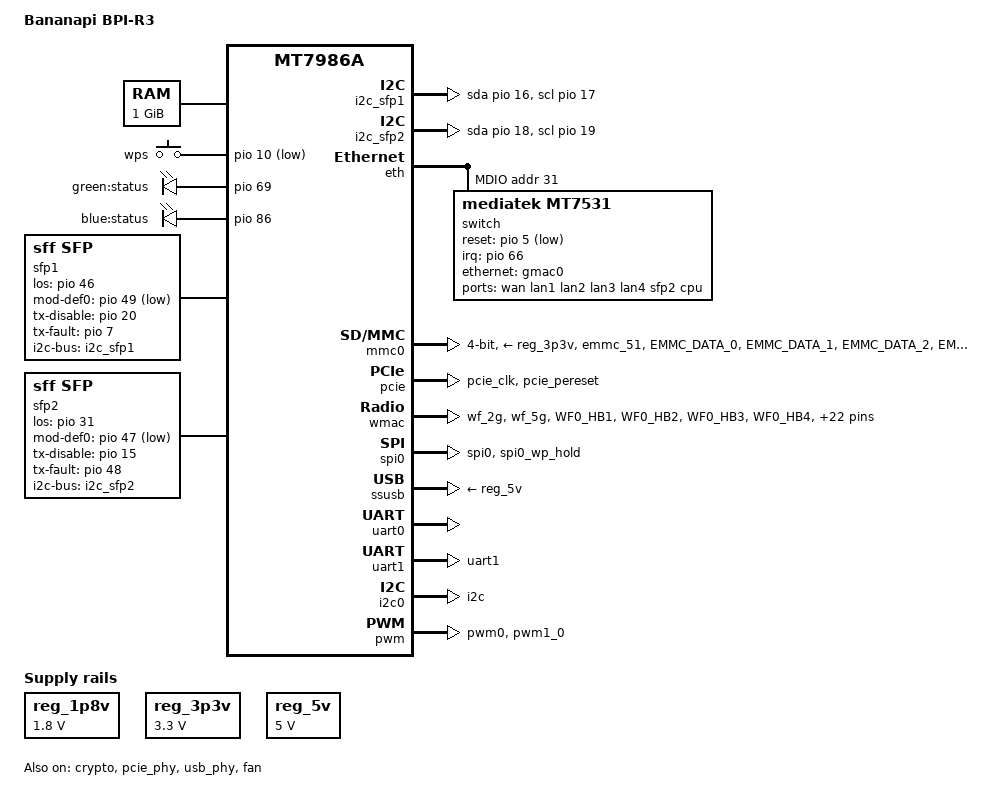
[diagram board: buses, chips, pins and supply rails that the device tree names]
// SPDX-License-Identifier: (GPL-2.0 OR MIT)
/*
 * Copyright (C) 2021 MediaTek Inc.
 * Author: Sam.Shih <sam.shih@mediatek.com>
 */

/dts-v1/;
#include <dt-bindings/input/input.h>
#include <dt-bindings/gpio/gpio.h>

#include "mt7986a.dtsi"

/ {
	model = "Bananapi BPI-R3";
	compatible = "bananapi,bpi-r3", "mediatek,mt7986a";

	aliases {
		serial0 = &uart0;
		ethernet0 = &gmac0;
		ethernet1 = &gmac1;
		led-boot = &led_status_green;
		led-failsafe = &led_status_green;
		led-running = &led_status_green;
		led-upgrade = &led_status_blue;
	};

	chosen {
		stdout-path = "serial0:115200n8";
	};

	memory@40000000 {
		device_type = "memory";
		reg = <0 0x40000000 0 0x40000000>;
	};

	reg_1p8v: regulator-1p8v {
		compatible = "regulator-fixed";
		regulator-name = "fixed-1.8V";
		regulator-min-microvolt = <1800000>;
		regulator-max-microvolt = <1800000>;
		regulator-boot-on;
		regulator-always-on;
	};

	reg_3p3v: regulator-3p3v {
		compatible = "regulator-fixed";
		regulator-name = "fixed-3.3V";
		regulator-min-microvolt = <3300000>;
		regulator-max-microvolt = <3300000>;
		regulator-boot-on;
		regulator-always-on;
	};

	reg_5v: regulator-5v {
		compatible = "regulator-fixed";
		regulator-name = "fixed-5V";
		regulator-min-microvolt = <5000000>;
		regulator-max-microvolt = <5000000>;
		regulator-boot-on;
		regulator-always-on;
	};

	keys {
		compatible = "gpio-keys";

/*
 * RST button is also PCIe-CLKREQ signal, use WPS button as reset
 * instead as RST button doesn't make sense and cannot be used.
 *
 * intended buttons:
		factory {
			label = "reset";
			linux,code = <KEY_RESTART>;
			gpios = <&pio 9 GPIO_ACTIVE_LOW>;
		};

		wps {
			label = "wps";
			linux,code = <KEY_WPS_BUTTON>;
			gpios = <&pio 10 GPIO_ACTIVE_LOW>;
		};
 * actual setup:
 */
		wps {
			label = "wps";
			linux,code = <KEY_RESTART>;
			gpios = <&pio 10 GPIO_ACTIVE_LOW>;
		};
	};

	leds {
		compatible = "gpio-leds";

		led_status_green: green {
			label = "green:status";
			gpios = <&pio 69 GPIO_ACTIVE_HIGH>;
			default-state = "on";
		};

		led_status_blue: blue {
			label = "blue:status";
			gpios = <&pio 86 GPIO_ACTIVE_HIGH>;
		};
	};

	/* SFP1 cage (WAN) */
	i2c_sfp1: i2c-gpio-0 {
		compatible = "i2c-gpio";
		sda-gpios = <&pio 16 (GPIO_ACTIVE_HIGH | GPIO_OPEN_DRAIN)>;
		scl-gpios = <&pio 17 (GPIO_ACTIVE_HIGH | GPIO_OPEN_DRAIN)>;
		i2c-gpio,delay-us = <2>;
		#address-cells = <1>;
		#size-cells = <0>;
	};

	sfp1: sfp1 {
		compatible = "sff,sfp";
		i2c-bus = <&i2c_sfp1>;
		los-gpios = <&pio 46 GPIO_ACTIVE_HIGH>;
		mod-def0-gpios = <&pio 49 GPIO_ACTIVE_LOW>;
		tx-disable-gpios = <&pio 20 GPIO_ACTIVE_HIGH>;
		tx-fault-gpios = <&pio 7 GPIO_ACTIVE_HIGH>;
	};

	/* SFP2 cage (LAN) */
	i2c_sfp2: i2c-gpio-1 {
		compatible = "i2c-gpio";
		sda-gpios = <&pio 18 (GPIO_ACTIVE_HIGH | GPIO_OPEN_DRAIN)>;
		scl-gpios = <&pio 19 (GPIO_ACTIVE_HIGH | GPIO_OPEN_DRAIN)>;
		i2c-gpio,delay-us = <2>;
		#address-cells = <1>;
		#size-cells = <0>;
	};

	sfp2: sfp2 {
		compatible = "sff,sfp";
		i2c-bus = <&i2c_sfp2>;
		los-gpios = <&pio 31 GPIO_ACTIVE_HIGH>;
		mod-def0-gpios = <&pio 47 GPIO_ACTIVE_LOW>;
		tx-disable-gpios = <&pio 15 GPIO_ACTIVE_HIGH>;
		tx-fault-gpios = <&pio 48 GPIO_ACTIVE_HIGH>;
	};
};

&eth {
	status = "okay";

	gmac0: mac@0 {
		compatible = "mediatek,eth-mac";
		reg = <0>;
		phy-mode = "2500base-x";

		fixed-link {
			speed = <2500>;
			full-duplex;
			pause;
		};
	};

	gmac1: mac@1 {
		compatible = "mediatek,eth-mac";
		reg = <1>;
		phy-mode = "2500base-x";
		sfp = <&sfp1>;
		managed = "in-band-status";
	};

	mdio: mdio-bus {
		#address-cells = <1>;
		#size-cells = <0>;
	};
};

&mdio {
	switch: switch@0 {
		compatible = "mediatek,mt7531";
		reg = <31>;
		reset-gpios = <&pio 5 GPIO_ACTIVE_LOW>;
		interrupt-controller;
		#interrupt-cells = <1>;
		interrupt-parent = <&pio>;
		interrupts = <66 IRQ_TYPE_LEVEL_HIGH>;
	};
};

&switch {
	ports {
		#address-cells = <1>;
		#size-cells = <0>;

		port@0 {
			reg = <0>;
			label = "wan";
		};

		port@1 {
			reg = <1>;
			label = "lan1";
		};

		port@2 {
			reg = <2>;
			label = "lan2";
		};

		port@3 {
			reg = <3>;
			label = "lan3";
		};

		port@4 {
			reg = <4>;
			label = "lan4";
		};

		port5: port@5 {
			reg = <5>;
			label = "sfp2";
			phy-mode = "2500base-x";
			sfp = <&sfp2>;
			managed = "in-band-status";
		};

		port@6 {
			reg = <6>;
			label = "cpu";
			ethernet = <&gmac0>;
			phy-mode = "2500base-x";

			fixed-link {
				speed = <2500>;
				full-duplex;
				pause;
			};
		};
	};
};

&crypto {
	status = "okay";
};

&mmc0 {
	//sdcard
	pinctrl-names = "default", "state_uhs";
	pinctrl-0 = <&mmc0_pins_default>;
	pinctrl-1 = <&mmc0_pins_uhs>;
	bus-width = <4>;
	max-frequency = <52000000>;
	cap-sd-highspeed;
	vmmc-supply = <&reg_3p3v>;
	vqmmc-supply = <&reg_1p8v>;
	status = "okay";
};

&pcie {
	pinctrl-names = "default";
	pinctrl-0 = <&pcie_pins>;
	status = "okay";
};

&pcie_phy {
	status = "okay";
};

&wmac {
	status = "okay";
	pinctrl-names = "default", "dbdc";
	pinctrl-0 = <&wf_2g_5g_pins>, <&wf_led_pins>;
	pinctrl-1 = <&wf_dbdc_pins>, <&wf_led_pins>;
};

&pio {
	/* don't mess around with GPIO 419, 450, 451, 498, 510 in sysfs system will freeze. */
	mmc0_pins_default: mmc0-pins {
		mux {
			function = "emmc";
			groups = "emmc_51";
		};
		conf-cmd-dat {
			pins = "EMMC_DATA_0", "EMMC_DATA_1", "EMMC_DATA_2",
			       "EMMC_DATA_3", "EMMC_DATA_4", "EMMC_DATA_5",
			       "EMMC_DATA_6", "EMMC_DATA_7", "EMMC_CMD";
			input-enable;
			drive-strength = <4>;
			mediatek,pull-up-adv = <1>;	/* pull-up 10K */
		};
		conf-clk {
			pins = "EMMC_CK";
			drive-strength = <6>;
			mediatek,pull-down-adv = <2>;	/* pull-down 50K */
		};
		conf-ds {
			pins = "EMMC_DSL";
			mediatek,pull-down-adv = <2>;	/* pull-down 50K */
		};
		conf-rst {
			pins = "EMMC_RSTB";
			drive-strength = <4>;
			mediatek,pull-up-adv = <1>;	/* pull-up 10K */
		};
	};

	mmc0_pins_uhs: mmc0-uhs-pins {
		mux {
			function = "emmc";
			groups = "emmc_51";
		};
		conf-cmd-dat {
			pins = "EMMC_DATA_0", "EMMC_DATA_1", "EMMC_DATA_2",
			       "EMMC_DATA_3", "EMMC_DATA_4", "EMMC_DATA_5",
			       "EMMC_DATA_6", "EMMC_DATA_7", "EMMC_CMD";
			input-enable;
			drive-strength = <4>;
			mediatek,pull-up-adv = <1>;	/* pull-up 10K */
		};
		conf-clk {
			pins = "EMMC_CK";
			drive-strength = <6>;
			mediatek,pull-down-adv = <2>;	/* pull-down 50K */
		};
		conf-ds {
			pins = "EMMC_DSL";
			mediatek,pull-down-adv = <2>;	/* pull-down 50K */
		};
		conf-rst {
			pins = "EMMC_RSTB";
			drive-strength = <4>;
			mediatek,pull-up-adv = <1>;	/* pull-up 10K */
		};
	};

	pcie_pins: pcie-pins {
		mux {
			function = "pcie";
			groups = "pcie_clk", "pcie_pereset"; //"pcie_wake" is unused
		};
	};

	spi_flash_pins: spi-flash-pins {
		mux {
			function = "spi";
			groups = "spi0", "spi0_wp_hold";
		};
	};

	uart1_pins: uart1-pins {
		mux {
			function = "uart";
			groups = "uart1";
		};
	};

	i2c0_pins: i2c0-pins {
		mux {
			function = "i2c";
			groups = "i2c";
		};
	};

	pwm_pins: pwm-pins {
		mux {
			function = "pwm";
			groups = "pwm0", "pwm1_0";
		};
	};

	wf_led_pins: wf-led-pins {
		mux {
			function = "led";
			groups = "wifi_led";
		};
	};

	wf_2g_5g_pins: wf-2g-5g-pins {
		mux {
			function = "wifi";
			groups = "wf_2g", "wf_5g";
		};
		conf {
			pins = "WF0_HB1", "WF0_HB2", "WF0_HB3", "WF0_HB4",
			       "WF0_HB0", "WF0_HB0_B", "WF0_HB5", "WF0_HB6",
			       "WF0_HB7", "WF0_HB8", "WF0_HB9", "WF0_HB10",
			       "WF0_TOP_CLK", "WF0_TOP_DATA", "WF1_HB1",
			       "WF1_HB2", "WF1_HB3", "WF1_HB4", "WF1_HB0",
			       "WF1_HB5", "WF1_HB6", "WF1_HB7", "WF1_HB8",
			       "WF1_TOP_CLK", "WF1_TOP_DATA";
			drive-strength = <4>;
		};
	};

	wf_dbdc_pins: wf-dbdc-pins {
		mux {
			function = "wifi";
			groups = "wf_dbdc";
		};
		conf {
			pins = "WF0_HB1", "WF0_HB2", "WF0_HB3", "WF0_HB4",
			       "WF0_HB0", "WF0_HB0_B", "WF0_HB5", "WF0_HB6",
			       "WF0_HB7", "WF0_HB8", "WF0_HB9", "WF0_HB10",
			       "WF0_TOP_CLK", "WF0_TOP_DATA", "WF1_HB1",
			       "WF1_HB2", "WF1_HB3", "WF1_HB4", "WF1_HB0",
			       "WF1_HB5", "WF1_HB6", "WF1_HB7", "WF1_HB8",
			       "WF1_TOP_CLK", "WF1_TOP_DATA";
			drive-strength = <4>;
		};
	};
};

&spi0 {
	pinctrl-names = "default";
	pinctrl-0 = <&spi_flash_pins>;

	status = "okay";
};

&ssusb {
	vusb33-supply = <&reg_3p3v>;
	vbus-supply = <&reg_5v>;
	status = "okay";
};

&uart0 {
	status = "okay";
};

&uart1 {
	pinctrl-names = "default";
	pinctrl-0 = <&uart1_pins>;
	status = "okay";
};

&usb_phy {
	status = "okay";
};

&i2c0 {
	pinctrl-names = "default";
	pinctrl-0 = <&i2c0_pins>;
	status = "okay";
};

&pwm {
	pinctrl-names = "default";
	pinctrl-0 = <&pwm_pins>;
	status = "okay";
};

&fan {
	pwms = <&pwm 0 10000 0>;
	cooling-levels = <255 96 52 0>;
	status = "okay";
};

&wmac {
	mediatek,eeprom-data = <0x86790900 0xc4326 0x60000000 0x00 0x00 0x00 0x00 0x00
				0x00 0x00 0x00 0x00 0x00 0x00 0x00 0x00
				0x00 0x00 0x00 0x00 0x00 0x00 0x00 0x1000000
				0x00 0x00 0x00 0x00 0x00 0x00 0x00 0x00
				0x00 0x00 0x00 0x00 0x00 0x00 0x00 0x00
				0x00 0x00 0x00 0x00 0x00 0x00 0x00 0x00
				0x00 0x00 0x00 0x00 0x00 0x00 0x00 0x00
				0x00 0x00 0x00 0x00 0x00 0x00 0x00 0x00
				0x00 0x800 0x00 0x00 0x00 0x00 0x00 0x00
				0x00 0x00 0x00 0x00 0x00 0x00 0x00 0x00
				0x00 0x00 0x00 0x00 0x00 0x00 0x00 0x00
				0x00 0x00 0x00 0x00 0x00 0x00 0x00 0x00
				0x00 0x00 0x00 0x00 0x24649090 0x280000 0x5100000 0x00
				0x00 0x00 0x00 0x00 0x00 0x00 0x00 0x00
				0x00 0x00 0x00 0x00 0x00 0x00 0x00 0x00
				0x00 0x00 0x00 0x00 0x00 0x00 0x00 0x00
				0x21e00 0x21e0002 0x1e00021e 0x22800 0x2280002 0x28000228 0x00 0x00
				0x00 0x00 0x00 0x00 0x00 0x00 0x8080 0x8080fdf7
				0x903150d 0x80808080 0x80808080 0x5050d0d 0x1313c6c6 0xc3c3c200 0xc200c2 0x8182
				0x8585c2c2 0x82828282 0x858500c2 0xc2000081 0x82858587 0x87c2c200 0x81818285 0x858787c2
				0xc2000081 0x82858587 0x87c2c200 0x818285 0x858787c2 0xc2000081 0x82858587 0x87c4c4c2
				0xc100c300 0xc3c3c100 0x818383c3 0xc3c3c100 0x81838300 0xc2c2c2c0 0x81828484 0xc3
				0xc3c3c100 0x81838386 0x86c3c3c3 0xc1008183 0x838686c2 0xc2c2c081 0x82848486 0x86c3c3c3
				0xc1008183 0x838686c3 0xc3c3c100 0x81838386 0x86c3c3c3 0xc1008183 0x83868622 0x28002228
				0x222800 0x22280000 0xdddddddd 0xdddddddd 0xddbbbbbb 0xccccccdd 0xdddddddd 0xdddddddd
				0xeeeeeecc 0xccccdddd 0xdddddddd 0x4a5662 0x4a 0x56620000 0x4a5662 0x4a
				0x56620000 0x88888888 0x33333326 0x26262626 0x26262600 0x33333326 0x26262626 0x26262600
				0x33333326 0x26262626 0x26262600 0x33333326 0x26262626 0x26262600 0x00 0xf0f0cc00
				0x00 0xaaaa 0xaabbbbbb 0xcccccccc 0xccccbbbb 0xbbbbbbbb 0xbbbbbbaa 0xaaaabbbb
				0xbbaaaaaa 0x999999aa 0xaaaabbbb 0xbbcccccc 0x00 0xaaaa 0xaa000000 0xbbbbbbbb
				0xbbbbaaaa 0xaa999999 0xaaaaaaaa 0xaaaaaaaa 0xaaaaaaaa 0xaaaaaaaa 0xaaaabbbb 0xbbbbbbbb
				0x00 0x00 0x00 0x99999999 0x9999aaaa 0xaaaaaaaa 0x999999aa 0xaaaaaaaa
				0xaaaaaaaa 0xaaaaaaaa 0xaaaabbbb 0xbbbbbbbb 0x00 0xeeee 0xeeffffff 0xcccccccc
				0xccccdddd 0xddbbbbbb 0xccccccbb 0xbbbbbbbb 0xbbbbbbbb 0xbbbbbbbb 0xbbbbcccc 0xccdddddd
				0x516200 0x686e0051 0x6200686e 0x516200 0x686e0051 0x6200686e 0x516200 0x686e0051
				0x6200686e 0x516200 0x686e0051 0x6200686e 0x516200 0x686e0051 0x6200686e 0x516200
				0x686e0051 0x6200686e 0x516200 0x686e0051 0x6200686e 0x516200 0x686e0051 0x6200686e
				0x516200 0x686e0051 0x6200686e 0x516200 0x686e0051 0x6200686e 0x516200 0x686e0051
				0x6200686e 0x516200 0x686e0051 0x6200686e 0x516200 0x686e0051 0x6200686e 0x516200
				0x686e0051 0x6200686e 0x516200 0x686e0051 0x6200686e 0x516200 0x686e0051 0x6200686e
				0x88888888 0x88888888 0x88888888 0x88888888 0x88888888 0x88888888 0x88888888 0x88888888
				0x00 0x00 0x00 0x00 0x00 0x00 0x00 0x00
				0x00 0x00 0x00 0x00 0x00 0x00 0x00 0x00
				0x00 0x00 0x00 0x00 0x00 0x00 0x00 0x00
				0x00 0x00 0x00 0x00 0x00 0x00 0x00 0x00
				0x00 0x00 0x00 0x00 0x00 0x00 0x00 0x00
				0x00 0x00 0x00 0x00 0x00 0x00 0x00 0x00
				0x00 0x00 0x00 0x00 0x00 0x00 0x00 0x00
				0x00 0x00 0x00 0x00 0x00 0x00 0x00 0x00
				0x00 0x00 0x00 0x00 0x00 0x00 0x00 0x00
				0x00 0x00 0x00 0x00 0x01 0x6000100 0x1050002 0xff0300
				0xf900fe03 0x00 0x00 0x9b 0x6e370000 0x00 0xfc0009 0xa00fe00
				0x60700fe 0x70800 0x5000b0a 0x00 0x00 0xe2 0x96460000 0x00
				0x400f7 0xf8000300 0xfcfe0003 0xfbfc00 0xee00e3f2 0x00 0x00 0x11
				0xbb550000 0x00 0x600f6 0xfc000300 0xfbfe0004 0xfafe00 0xf600ecf2 0x00
				0x00 0x1f 0xbf580000 0x00 0x600f5 0xf6000400 0xf8f90004 0xf7f800
				0xf700f0f4 0x00 0x00 0x24 0xbe570000 0x00 0x800f8 0xfe000600
				0xf8fd0007 0xf9fe00 0xf500f0f4 0x00 0x00 0x2d 0xd6610000 0x00
				0x400f7 0xfc000500 0xf7fc0005 0xf7fc00 0xf900f5f8 0x00 0x00 0x26
				0xd96e0000 0x00 0x400f7 0xf9000600 0xf5f70005 0xf5f800 0xf900f4f7 0x00
				0x00 0x1b 0xce690000 0x00 0x300f8 0xf8000600 0xf6f60004 0xf6f700
				0xf900f4f7 0x00 0x00 0x18 0xd8720000 0x00 0x00 0x2404002
				0x00 0x00 0x00 0x00 0x00 0x00 0x00 0x00
				0x00 0x00 0x00 0x00 0x00 0x00 0x00 0x00
				0x00 0x00 0x00 0x00 0x00 0x00 0x00 0x00
				0x00 0x00 0x00 0x00 0x00 0x00 0x00 0x00
				0x00 0x00 0x00 0x00 0x00 0x00 0x00 0x00
				0x00 0x00 0x00 0x00 0x00 0x00 0x00 0x00
				0x00 0x00 0x00 0x00 0x00 0x00 0x00 0x00
				0x00 0x00 0x00 0x00 0x00 0x00 0x00 0x00
				0x00 0x00 0x00 0x00 0x00 0x00 0x00 0x00
				0x00 0x00 0x00 0x00 0x00 0x00 0x00 0x00
				0xc1c2c1c2 0x41c341c3 0x3fc13fc1 0x40c13fc2 0x3fc240c1 0x41c040c0 0x3fc23fc2 0x40c13fc2
				0x3fc140c0 0x41c040c0 0x3fc33fc3 0x40c23fc2 0x3fc240c1 0x41c040c0 0x3fc23fc2 0x40c23fc2
				0x3fc140c1 0x41c040c0 0x00 0x00 0x41c741c7 0xc1c7c1c7 0x00 0x00
				0x3fc03fc0 0x3fc03fc0 0x3fc03fc0 0x3fc03fc0 0x3fc03fc0 0x3fc03fc0 0x3fc03fc0 0x3fc03fc0
				0x3fc03fc0 0x3fc03fc0 0x3fc03fc0 0x3fc03fc0 0x3fc03fc0 0x3fc03fc0 0x3fc03fc0 0x3fc03fc0
				0xa0ce00 0x00 0xb6840000 0x00 0x00 0x00 0x18181818 0x18181818
				0x00 0x00 0x00 0x00 0x00 0x00 0x00 0x00
				0x00 0x00 0x00 0x00 0x00 0x00 0x00 0x00
				0x4b5763 0x4b 0x57630000 0x4b5763 0x4b 0x57630000 0x88888888 0x8474759
				0x69780849 0x49596d7a 0x849495a 0x6d790848 0x48596c78 0x8484858 0x6a780848 0x48586a78
				0x8484858 0x6c78084a 0x4a5b6d79 0x8474759 0x697a0848 0x48596b79 0x8484859 0x6c7a0848
				0x48586c79 0x8484857 0x68770848 0x48576877 0x8484857 0x6a77084a 0x4a5a6a77 0x8464659
				0x69790848 0x48586b79 0x8484858 0x6c7a0848 0x48596c79 0x8484857 0x68770848 0x48576877
				0x8494958 0x6d7a084b 0x4b5c6c77 0x847475a 0x6a7b0849 0x495a6e7c 0x849495a 0x6e7c0849
				0x495b6e7c 0x8494959 0x6a7a0849 0x49596a7a 0x84a4a5a 0x6f7d084b 0x4b5c6e7b 0x00
				0x00 0x00 0x00 0x00 0x00 0x00 0x00 0x85848484
				0xc3c4c4c5 0xc4c3c33f 0xc3c3c2c2 0xc2c2c03f 0xc3c3c3c4 0xc4c4c33f 0xc2c2c2c2 0xc1c3c1c1
				0xc0c08282 0x83848686 0x88880000 0x00 0x00 0x00 0x00 0x00
				0x00 0x00 0x00 0x00 0x00 0x00 0x00 0x00
				0x00 0x00 0x00 0x00 0x00 0x00 0x00 0x00
				0x00 0x00 0x00 0x00 0x00 0x00 0x00 0x00
				0x00 0x00 0x00 0x00 0x00 0x00 0x00 0x00
				0x00 0x00 0x00 0x00 0x00 0x00 0x00 0x00
				0x00 0x00 0x00 0x00 0x00 0x00 0x00 0x00
				0x00 0x00 0x00 0x00 0x00 0x00 0x00 0x00
				0x00 0x00 0x00 0x00 0x00 0x00 0x00 0x00
				0x00 0x00 0x00 0x00 0x00 0x00 0x00 0x00
				0x00 0x00 0x00 0x00 0x00 0x00 0x00 0x00
				0x00 0x00 0x00 0x00 0x00 0x00 0x00 0x00
				0x00 0x00 0x00 0x00 0x00 0x00 0x00 0x00
				0x00 0x00 0x00 0x00 0x00 0x00 0x00 0x00
				0x00 0x00 0x00 0x00 0x00 0x00 0x00 0x00
				0x00 0x00 0x00 0x00 0x00 0x00 0x00 0x00
				0x00 0x00 0x00 0x00 0x00 0x00 0x00 0x00
				0x00 0x00 0x00 0x00 0x00 0x00 0x00 0x00
				0x00 0x00 0x00 0x00 0x00 0x00 0x1111 0x00
				0x8080f703 0x10808080 0x80050d13 0x00 0x00 0x00 0x00 0x00
				0x00 0x00 0x00 0x00 0x00 0x00 0x00 0x00
				0x00 0x00 0x00 0x00 0x00 0x00 0x00 0x00
				0x00 0x00 0x00 0x00 0x00 0x00 0x00 0x00
				0x00 0x00 0x00 0x00 0x00 0x00 0x00 0x00
				0x00 0x00 0x00 0xa4 0xce000000 0xb684 0x00 0x00
				0x00 0x00 0x00 0x00 0x00 0x00 0x00 0x00
				0x00 0x00 0x00 0x00 0x00 0x00 0x00 0x00
				0x00 0x00 0x00 0x00 0x00 0x00 0x00 0x00
				0x00 0x00 0x00 0x00 0x00 0x00 0x00 0x00
				0x00 0x00 0x00 0x00 0x00 0x00 0x00 0x00
				0x00 0x00 0x00 0x00 0x00 0x00 0x00 0x00
				0x00 0x00 0x00 0x00 0x00 0x00 0x00 0x00
				0x00 0x00 0x00 0x00 0x00 0x00 0x00 0x00
				0x00 0x00 0x00 0x00 0x00 0x00 0x00 0x00
				0x00 0x00 0x00 0x00 0x00 0x00 0x00 0x00
				0x00 0x00 0x00 0x00 0x00 0x00 0x00 0x00
				0x00 0x00 0x00 0x00 0x00 0x00 0x00 0x00
				0x00 0x00 0x00 0x00 0x00 0x00 0x00 0x00
				0x00 0x00 0x00 0x00 0x00 0x00 0x00 0x00>;
};
